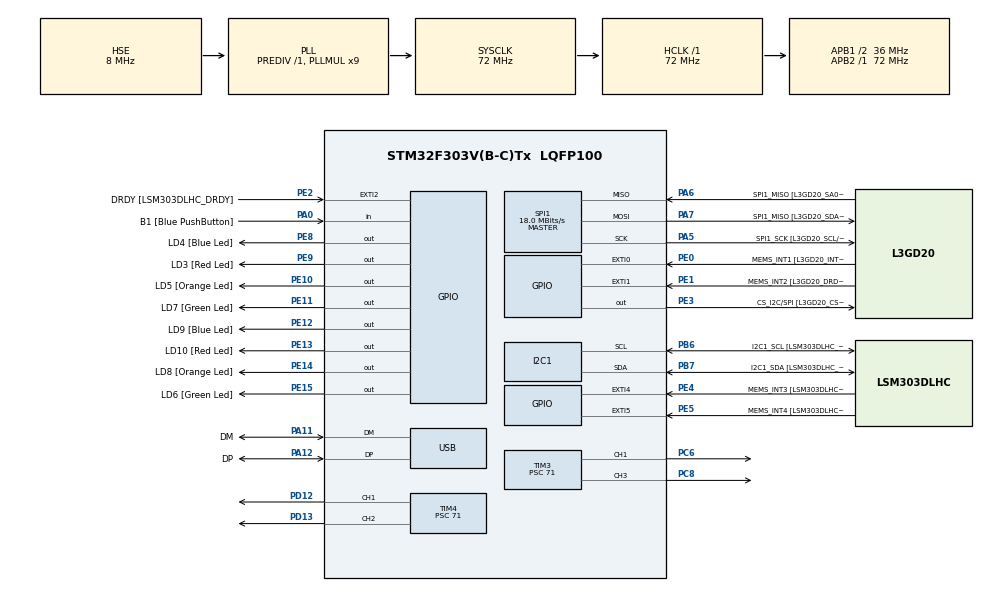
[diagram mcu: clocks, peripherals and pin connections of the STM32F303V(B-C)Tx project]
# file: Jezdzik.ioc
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I2C1.Timing-I2C=0x2000090E
Mcu.Family=STM32F3
Mcu.Name=STM32F303V(B-C)Tx
Mcu.Package=LQFP100
NVIC.PriorityGroup=NVIC_PRIORITYGROUP_0
NVIC.TIM1_UP_TIM16_IRQn=true\:0\:0\:false\:false\:true\:true
NVIC.TIM3_IRQn=true\:0\:0\:false\:false\:true\:true
NVIC.TIM4_IRQn=true\:0\:0\:false\:false\:true\:true
PA0.GPIO_Label=B1 [Blue PushButton]
PA0.Signal=GPIO_Input
PA11.GPIO_Label=DM
PA11.Mode=Device
PA11.Signal=USB_DM
PA12.GPIO_Label=DP
PA12.Mode=Device
PA12.Signal=USB_DP
PA13.GPIO_Label=SWDIO
PA13.Mode=Serial_Wire
PA13.Signal=SYS_JTMS-SWDIO
PA14.GPIO_Label=SWCLK
PA14.Mode=Serial_Wire
PA14.Signal=SYS_JTCK-SWCLK
PA5.GPIO_Label=SPI1_SCK [L3GD20_SCL/SPC]
PA5.Mode=Full_Duplex_Master
PA5.Signal=SPI1_SCK
PA6.GPIO_Label=SPI1_MISO [L3GD20_SA0/SDO]
PA6.Mode=Full_Duplex_Master
PA6.Signal=SPI1_MISO
PA7.GPIO_Label=SPI1_MISO [L3GD20_SDA/SDI/SDO]
PA7.Mode=Full_Duplex_Master
PA7.Signal=SPI1_MOSI
PB3.GPIO_Label=SWO
PB3.Signal=SYS_JTDO-TRACESWO
PB6.GPIO_Label=I2C1_SCL [LSM303DLHC_SCL]
PB6.Mode=I2C
PB6.Signal=I2C1_SCL
PB7.GPIO_Label=I2C1_SDA [LSM303DLHC_SDA]
PB7.Mode=I2C
PB7.Signal=I2C1_SDA
PC14-OSC32_IN.GPIO_Label=OSC32_IN
PC14-OSC32_IN.Signal=RCC_OSC32_IN
PC15-OSC32_OUT.GPIO_Label=OSC32_OUT
PC15-OSC32_OUT.Signal=RCC_OSC32_OUT
PC6.Signal=S_TIM3_CH1
PC8.Signal=S_TIM3_CH3
PD12.Signal=S_TIM4_CH1
PD13.Signal=S_TIM4_CH2
PE0.GPIO_Label=MEMS_INT1 [L3GD20_INT1]
PE0.GPIO_ModeDefaultEXTI=GPIO_MODE_EVT_RISING
PE0.Signal=GPXTI0
PE1.GPIO_Label=MEMS_INT2 [L3GD20_DRDY/INT2]
PE1.GPIO_ModeDefaultEXTI=GPIO_MODE_EVT_RISING
PE1.Signal=GPXTI1
PE10.GPIO_Label=LD5 [Orange Led]
PE10.Signal=GPIO_Output
PE11.GPIO_Label=LD7 [Green Led]
PE11.Signal=GPIO_Output
PE12.GPIO_Label=LD9 [Blue Led]
PE12.Signal=GPIO_Output
PE13.GPIO_Label=LD10 [Red Led]
PE13.Signal=GPIO_Output
PE14.GPIO_Label=LD8 [Orange Led]
PE14.Signal=GPIO_Output
PE15.GPIO_Label=LD6 [Green Led]
PE15.Signal=GPIO_Output
PE2.GPIO_Label=DRDY [LSM303DLHC_DRDY]
PE2.GPIO_ModeDefaultEXTI=GPIO_MODE_EVT_RISING
PE2.Signal=GPXTI2
PE3.GPIO_Label=CS_I2C/SPI [L3GD20_CS_I2C/SPI]
PE3.Signal=GPIO_Output
PE4.GPIO_Label=MEMS_INT3 [LSM303DLHC_INT1]
PE4.GPIO_ModeDefaultEXTI=GPIO_MODE_EVT_RISING
PE4.Signal=GPXTI4
PE5.GPIO_Label=MEMS_INT4 [LSM303DLHC_INT2]
PE5.GPIO_ModeDefaultEXTI=GPIO_MODE_EVT_RISING
PE5.Signal=GPXTI5
PE8.GPIO_Label=LD4 [Blue Led]
PE8.Signal=GPIO_Output
PE9.GPIO_Label=LD3 [Red Led]
PE9.Signal=GPIO_Output
PF0-OSC_IN.GPIO_Label=OSC_IN
PF0-OSC_IN.Mode=HSE-External-Clock-Source
PF0-OSC_IN.Signal=RCC_OSC_IN
PF1-OSC_OUT.GPIO_Label=OSC_OUT
PF1-OSC_OUT.Signal=RCC_OSC_OUT
ProjectManager.HeapSize=0x200
ProjectManager.StackSize=0x400
ProjectManager.TargetToolchain=TrueSTUDIO
RCC.AHBFreq_Value=72000000
RCC.APB1CLKDivider=RCC_HCLK_DIV2
RCC.APB1Freq_Value=36000000
RCC.APB1TimFreq_Value=72000000
RCC.APB2Freq_Value=72000000
RCC.APB2TimFreq_Value=72000000
RCC.CortexFreq_Value=72000000
RCC.HCLKFreq_Value=72000000
RCC.HSE_VALUE=8000000
RCC.HSI_VALUE=8000000
RCC.LSE_VALUE=32768
RCC.PLLMUL=RCC_PLL_MUL9
RCC.PRESCALERUSB=RCC_USBCLKSOURCE_PLL_DIV1_5
RCC.SYSCLKFreq_VALUE=72000000
RCC.SYSCLKSourceVirtual=RCC_SYSCLKSOURCE_PLLCLK
RCC.USBFreq_Value=48000000
SH.S_TIM3_CH1.0=TIM3_CH1,PWM Generation1 CH1
SH.S_TIM3_CH3.0=TIM3_CH3,PWM Generation3 CH3
SH.S_TIM4_CH1.0=TIM4_CH1,PWM Generation1 CH1
SH.S_TIM4_CH2.0=TIM4_CH2,PWM Generation2 CH2
SPI1.BaudRatePrescaler=SPI_BAUDRATEPRESCALER_4
SPI1.BaudRatePrescaler-Full_Duplex_Master=SPI_BAUDRATEPRESCALER_2
SPI1.CalculateBaudRate=18.0 MBits/s
SPI1.CalculateBaudRate-Full_Duplex_Master=24.0 MBits/s
SPI1.Direction=SPI_DIRECTION_2LINES
SPI1.Mode=SPI_MODE_MASTER
SPI1.Mode-Full_Duplex_Master=SPI_MODE_MASTER
SPI1.VirtualType=VM_MASTER
TIM16.Period=999
TIM16.Prescaler=71
TIM3.Channel-PWM\ Generation1\ CH1=TIM_CHANNEL_1
TIM3.Channel-PWM\ Generation3\ CH3=TIM_CHANNEL_3
TIM3.Period=999
TIM3.Prescaler=71
TIM4.Channel-PWM\ Generation1\ CH1=TIM_CHANNEL_1
TIM4.Channel-PWM\ Generation2\ CH2=TIM_CHANNEL_2
TIM4.Period=999
TIM4.Prescaler=71
VP_TIM16_VS_ClockSourceINT.Mode=Enable_Timer
VP_TIM3_VS_ClockSourceINT.Mode=Internal
VP_TIM4_VS_ClockSourceINT.Mode=Internal
board=STM32F3DISCOVERY

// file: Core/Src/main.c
/**
  ******************************************************************************
  * @file           : main.c
  * @brief          : Main program body
  ******************************************************************************
  ** This notice applies to any and all portions of this file
  * that are not between comment pairs USER CODE BEGIN and
  * USER CODE END. Other portions of this file, whether
  * inserted by the user or by software development tools
  * are owned by their respective copyright owners.
  *
  * COPYRIGHT(c) 2018 STMicroelectronics
  *
  * Redistribution and use in source and binary forms, with or without modification,
  * are permitted provided that the following conditions are met:
  *   1. Redistributions of source code must retain the above copyright notice,
  *      this list of conditions and the following disclaimer.
  *   2. Redistributions in binary form must reproduce the above copyright notice,
  *      this list of conditions and the following disclaimer in the documentation
  *      and/or other materials provided with the distribution.
  *   3. Neither the name of STMicroelectronics nor the names of its contributors
  *      may be used to endorse or promote products derived from this software
  *      without specific prior written permission.
  *
  * THIS SOFTWARE IS PROVIDED BY THE COPYRIGHT HOLDERS AND CONTRIBUTORS "AS IS"
  * AND ANY EXPRESS OR IMPLIED WARRANTIES, INCLUDING, BUT NOT LIMITED TO, THE
  * IMPLIED WARRANTIES OF MERCHANTABILITY AND FITNESS FOR A PARTICULAR PURPOSE ARE
  * DISCLAIMED. IN NO EVENT SHALL THE COPYRIGHT HOLDER OR CONTRIBUTORS BE LIABLE
  * FOR ANY DIRECT, INDIRECT, INCIDENTAL, SPECIAL, EXEMPLARY, OR CONSEQUENTIAL
  * DAMAGES (INCLUDING, BUT NOT LIMITED TO, PROCUREMENT OF SUBSTITUTE GOODS OR
  * SERVICES; LOSS OF USE, DATA, OR PROFITS; OR BUSINESS INTERRUPTION) HOWEVER
  * CAUSED AND ON ANY THEORY OF LIABILITY, WHETHER IN CONTRACT, STRICT LIABILITY,
  * OR TORT (INCLUDING NEGLIGENCE OR OTHERWISE) ARISING IN ANY WAY OUT OF THE USE
  * OF THIS SOFTWARE, EVEN IF ADVISED OF THE POSSIBILITY OF SUCH DAMAGE.
  *
  ******************************************************************************
  */
#include "main.h"
#include "stm32f3xx_hal.h"
#include "i2c.h"
#include "spi.h"
#include "tim.h"
#include "usb.h"
#include "gpio.h"

/* USER CODE BEGIN Includes */
#include "sub_main.h"
/* USER CODE END Includes */

/* USER CODE BEGIN PV */
/* Private variables ---------------------------------------------------------*/

/* USER CODE END PV */

void SystemClock_Config(void);

/* USER CODE BEGIN PFP */
/* Private function prototypes -----------------------------------------------*/

/* USER CODE END PFP */

int main(void)
{

  /* MCU Configuration----------------------------------------------------------*/

  /* Reset of all peripherals, Initializes the Flash interface and the Systick. */
  HAL_Init();

  /* Configure the system clock */
  SystemClock_Config();

  /* Initialize all configured peripherals */
  MX_GPIO_Init();
  MX_I2C1_Init();
  MX_SPI1_Init();
  MX_USB_PCD_Init();
  MX_TIM16_Init();
  MX_TIM3_Init();
  MX_TIM4_Init();
  /* USER CODE BEGIN 2 */
  HAL_TIM_Base_Start_IT(&htim16);
  /* USER CODE END 2 */

  /* Infinite loop */
  /* USER CODE BEGIN WHILE */
  while (1)
  {
	  loop();
  /* USER CODE END WHILE */

  }

}

void SystemClock_Config(void)
{

  RCC_OscInitTypeDef RCC_OscInitStruct;
  RCC_ClkInitTypeDef RCC_ClkInitStruct;
  RCC_PeriphCLKInitTypeDef PeriphClkInit;

    /**Initializes the CPU, AHB and APB busses clocks
    */
  RCC_OscInitStruct.OscillatorType = RCC_OSCILLATORTYPE_HSI|RCC_OSCILLATORTYPE_HSE;
  RCC_OscInitStruct.HSEState = RCC_HSE_BYPASS;
  RCC_OscInitStruct.HSEPredivValue = RCC_HSE_PREDIV_DIV1;
  RCC_OscInitStruct.HSIState = RCC_HSI_ON;
  RCC_OscInitStruct.HSICalibrationValue = 16;
  RCC_OscInitStruct.PLL.PLLState = RCC_PLL_ON;
  RCC_OscInitStruct.PLL.PLLSource = RCC_PLLSOURCE_HSE;
  RCC_OscInitStruct.PLL.PLLMUL = RCC_PLL_MUL9;
  if (HAL_RCC_OscConfig(&RCC_OscInitStruct) != HAL_OK)
  {
    _Error_Handler(__FILE__, __LINE__);
  }

    /**Initializes the CPU, AHB and APB busses clocks
    */
  RCC_ClkInitStruct.ClockType = RCC_CLOCKTYPE_HCLK|RCC_CLOCKTYPE_SYSCLK
                              |RCC_CLOCKTYPE_PCLK1|RCC_CLOCKTYPE_PCLK2;
  RCC_ClkInitStruct.SYSCLKSource = RCC_SYSCLKSOURCE_PLLCLK;
  RCC_ClkInitStruct.AHBCLKDivider = RCC_SYSCLK_DIV1;
  RCC_ClkInitStruct.APB1CLKDivider = RCC_HCLK_DIV2;
  RCC_ClkInitStruct.APB2CLKDivider = RCC_HCLK_DIV1;

  if (HAL_RCC_ClockConfig(&RCC_ClkInitStruct, FLASH_LATENCY_2) != HAL_OK)
  {
    _Error_Handler(__FILE__, __LINE__);
  }

  PeriphClkInit.PeriphClockSelection = RCC_PERIPHCLK_USB|RCC_PERIPHCLK_I2C1;
  PeriphClkInit.I2c1ClockSelection = RCC_I2C1CLKSOURCE_HSI;
  PeriphClkInit.USBClockSelection = RCC_USBCLKSOURCE_PLL_DIV1_5;
  if (HAL_RCCEx_PeriphCLKConfig(&PeriphClkInit) != HAL_OK)
  {
    _Error_Handler(__FILE__, __LINE__);
  }

    /**Configure the Systick interrupt time
    */
  HAL_SYSTICK_Config(HAL_RCC_GetHCLKFreq()/1000);

    /**Configure the Systick
    */
  HAL_SYSTICK_CLKSourceConfig(SYSTICK_CLKSOURCE_HCLK);

  /* SysTick_IRQn interrupt configuration */
  HAL_NVIC_SetPriority(SysTick_IRQn, 0, 0);
}

void _Error_Handler(char *file, int line)
{
  while(1)
  {
  }
}

/************************ (C) COPYRIGHT STMicroelectronics *****END OF FILE****/
